# f29h85x_mdl_xbar_regs register map
Vendor: Texas Instruments
Peripheral module from a debugger description file (folder C29).
Registers are 32-bit, read-write, no defined reset value unless marked. A register's access mark holds for its fields unless they carry their own. Offsets are as the file gives them; lines under a group give offsets from that group; [hi:lo] are bit positions; {n}, {i} and the like mark numbered series; 'fields as' and 'values as' point back to an identical list; <NAME> marks a mode.

## MDL_XBAR_REGS — MDL XBAR Registers
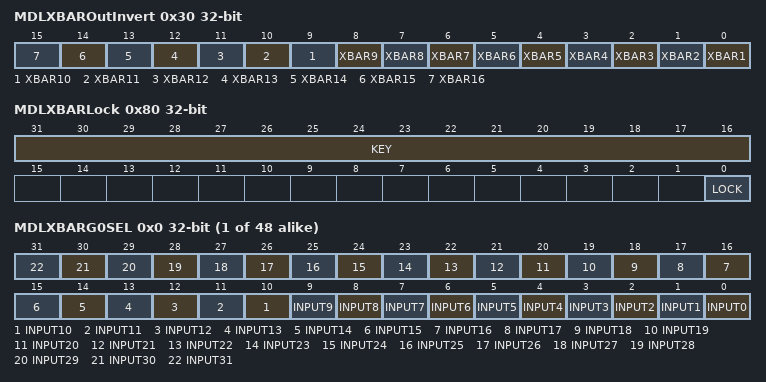
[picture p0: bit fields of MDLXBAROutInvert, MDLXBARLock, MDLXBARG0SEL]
0x30 MDLXBAROutInvert — Output Signal Invert Select
  [n-1] XBAR{n} (n=1..16) — Invert XBAR Output Select for XBAR{n}
0x80 MDLXBARLock — Configuration Lock register
  [31:16] KEY — Write protection KEY
  [0] LOCK — Locks the configuration for EMDL-XBAR
{0x100+0x40*i} MDL_XBAR_REGS_RegisterFile0[{i}] (i=0..15) group
  {0x0+4j} MDLXBARG{j}SEL (j=0..2) — MDLXBAR G{j} Input Select
    [n] INPUT{n} (n=0..31) — Select bit for INPUT{n}
